# Shared_Reference_3 register map
Vendor: Texas Instruments
Peripheral module from a debugger description file (folder msp430).
Registers are 16-bit, read-write, reset 0x0 unless marked. A register's access mark holds for its fields unless they carry their own. Offsets are as the file gives them; lines under a group give offsets from that group; [hi:lo] are bit positions; {n}, {i} and the like mark numbered series; 'fields as' and 'values as' point back to an identical list; <NAME> marks a mode.

## Shared_Reference
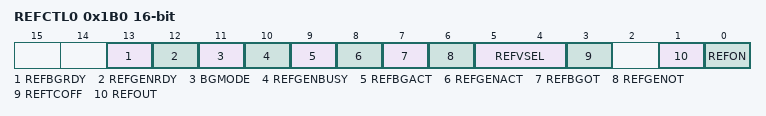
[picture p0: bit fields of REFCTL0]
0x1B0 REFCTL0 — REF Shared Reference control register 0
  [13] REFBGRDY — REF Reference bandgap ready
  [12] REFGENRDY — REF Reference generator ready
  [11] BGMODE — REF Bandgap mode
  [10] REFGENBUSY — REF Reference generator busy
  [9] REFBGACT — REF Reference bandgap active
  [8] REFGENACT — REF Reference generator active
  [7] REFBGOT — REF Bandgap and bandgap buffer one-time trigger
  [6] REFGENOT — REF Reference generator one-time trigger
  [5:4] REFVSEL — REF Reference Voltage Level Select Bit:0
    0=REF Reference Voltage Level Select 1.2V; 1=REF Reference Voltage Level Select 2.0V; 2=REF Reference Voltage Level Select 2.5V; 3=REF Reference Voltage Level Select 2.5V
  [3] REFTCOFF — REF Temp.Sensor off
  [1] REFOUT — REF Reference output Buffer On
  [0] REFON — REF Reference On
